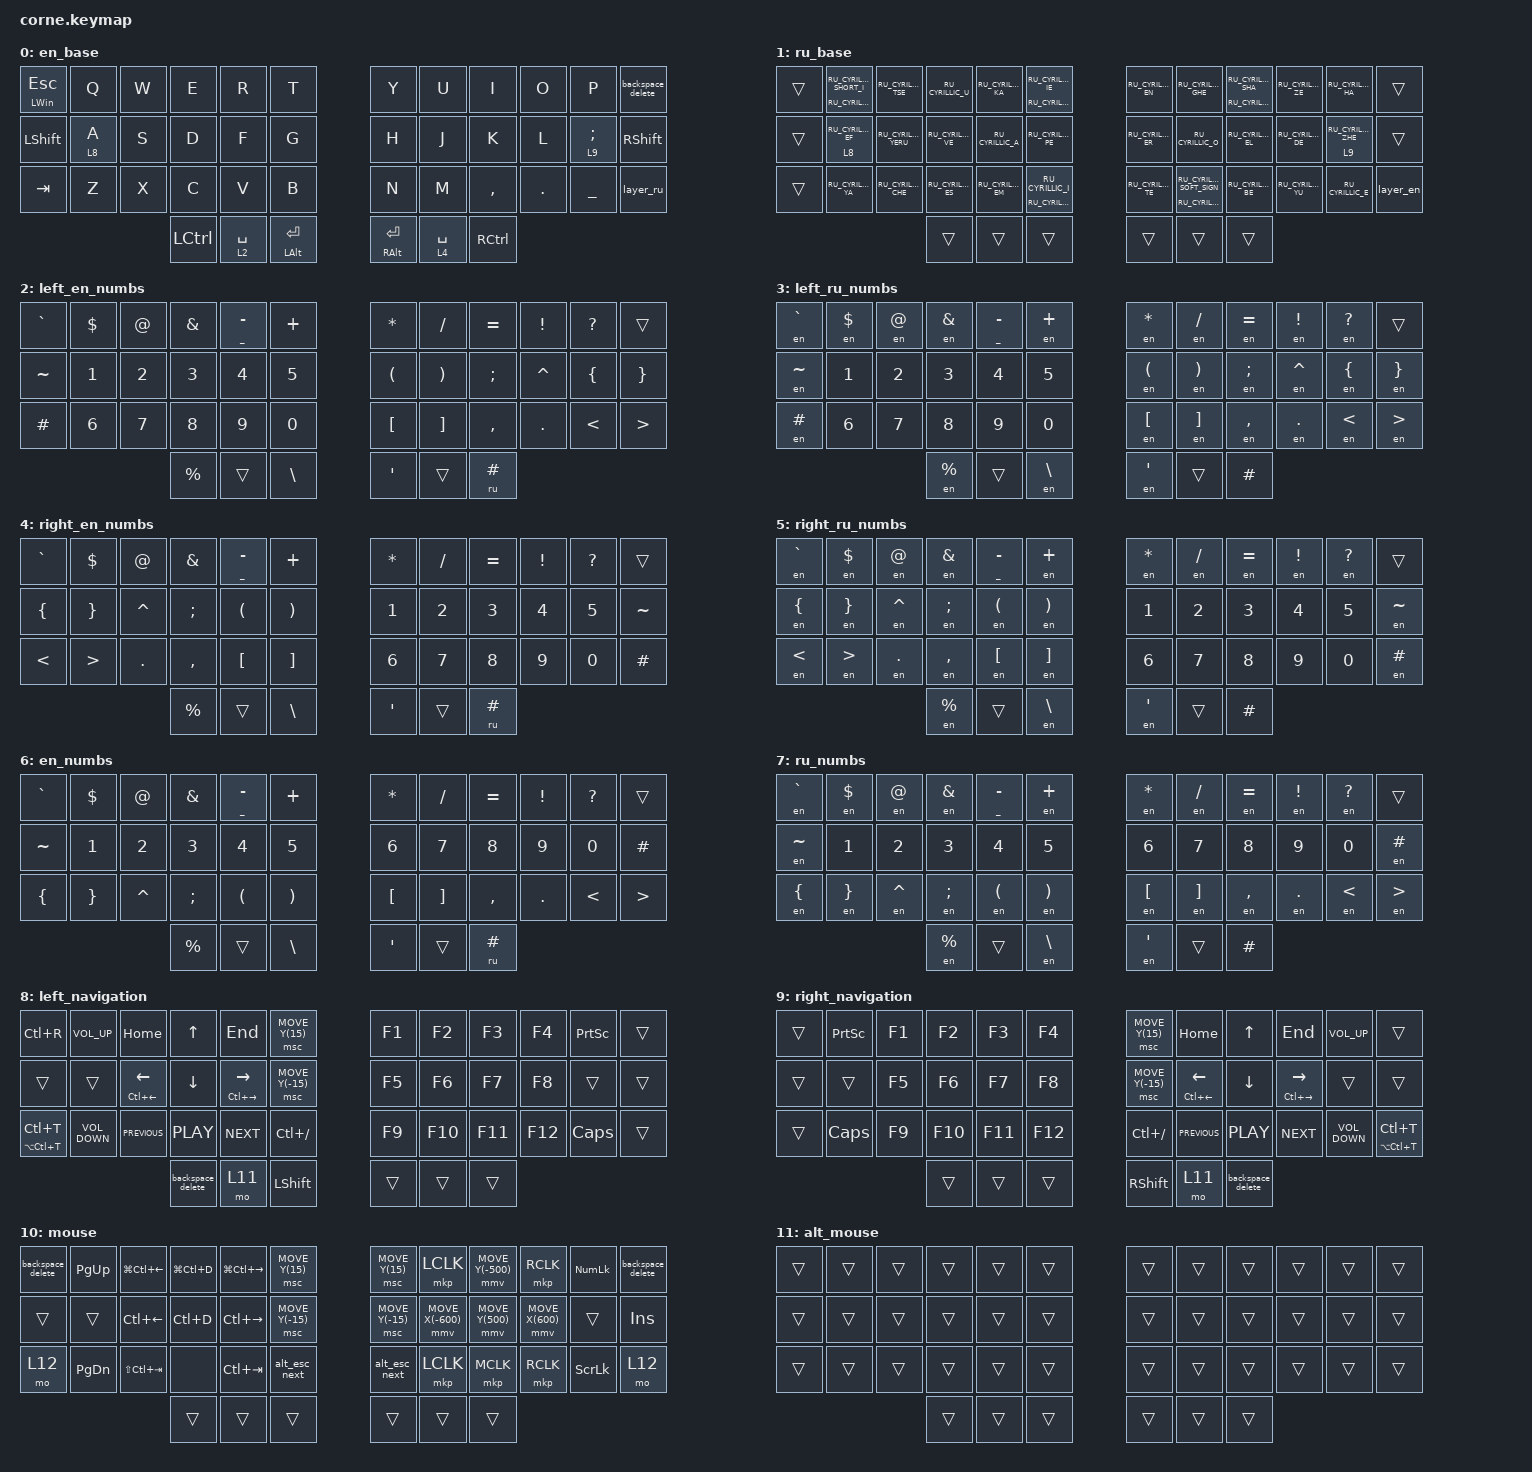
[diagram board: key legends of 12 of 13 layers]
/*
 * Copyright (c) 2020 The ZMK Contributors
 *
 * SPDX-License-Identifier: MIT
 */

#define ZMK_POINTING_DEFAULT_MOVE_VAL 1500  // default: 600
#define ZMK_POINTING_DEFAULT_SCRL_VAL 20    // default: 10

#include "keys_ru.h"
#include <behaviors.dtsi>
#include <dt-bindings/zmk/bt.h>
#include <dt-bindings/zmk/keys.h>
#include <dt-bindings/zmk/outputs.h>
#include <dt-bindings/zmk/pointing.h>

/ {
    combos { compatible = "zmk,combos"; };

    behaviors {
        hml: hml {
            compatible = "zmk,behavior-hold-tap";
            label = "HML";
            bindings = <&kp>, <&kp>;

            #binding-cells = <2>;
            tapping-term-ms = <220>;
            quick-tap-ms = <175>;
            flavor = "balanced";
            require-prior-idle-ms = <100>;
            hold-trigger-key-positions = <39 40 41 30 18 6 7 9 10 11 18 19 20 21 22 23 30 31 32 33 34 35 40 41 8 36 37 38>;
            hold-trigger-on-release;
        };

        hmr: hmr {
            compatible = "zmk,behavior-hold-tap";
            label = "HMR";
            bindings = <&kp>, <&kp>;

            #binding-cells = <2>;
            tapping-term-ms = <220>;
            quick-tap-ms = <175>;
            require-prior-idle-ms = <100>;
            flavor = "balanced";
            hold-trigger-key-positions = <0 1 2 3 4 5 12 13 14 15 16 17 24 25 26 27 28 29 36 37 38 39 40 41>;
            hold-trigger-on-release;
        };

        tkl: tkl {
            compatible = "zmk,behavior-hold-tap";
            label = "TKL";
            bindings = <&mo>, <&kp>;

            #binding-cells = <2>;
            tapping-term-ms = <220>;
            quick-tap-ms = <175>;
            flavor = "balanced";
            require-prior-idle-ms = <100>;
            hold-trigger-key-positions = <39 40 41 30 18 6 7 9 10 11 18 19 20 21 22 23 30 31 32 33 34 35 40 41 8 38 37 36>;
            hold-trigger-on-release;
        };

        tkr: tkr {
            compatible = "zmk,behavior-hold-tap";
            label = "TKR";
            bindings = <&mo>, <&kp>;

            #binding-cells = <2>;
            tapping-term-ms = <220>;
            quick-tap-ms = <175>;
            require-prior-idle-ms = <100>;
            flavor = "balanced";
            hold-trigger-key-positions = <0 1 2 3 4 5 12 13 14 15 16 17 24 25 26 27 28 29 36 37 38 39 40 41>;
            hold-trigger-on-release;
        };

        on: on {
            compatible = "zmk,behavior-toggle-layer";
            #binding-cells = <1>;
            toggle-mode = "on";
        };

        off: off {
            compatible = "zmk,behavior-toggle-layer";
            #binding-cells = <1>;
            toggle-mode = "off";
        };

        backspace_delete: backspace_delete {
            compatible = "zmk,behavior-mod-morph";
            label = "BACKSPACE_DELETE";
            bindings = <&hml LC(BACKSPACE) BACKSPACE>, <&hml LC(DELETE) DELETE>;

            #binding-cells = <0>;
            mods = <(MOD_LSFT|MOD_RSFT|MOD_LALT|MOD_RALT)>;
        };
    };

    macros {
        layer_en: layer_en {
            compatible = "zmk,behavior-macro";
            #binding-cells = <0>;
            bindings = <&off 1>, <&macro_tap>, <&kp LA(LS(NUMBER_0))>;

            label = "LAYER_EN";
        };

        layer_ru: layer_ru {
            compatible = "zmk,behavior-macro";
            #binding-cells = <0>;
            bindings = <&on 1>, <&macro_tap>, <&kp LA(LS(NUMBER_1))>;

            label = "LAYER_RU";
        };

        en: en {
            compatible = "zmk,behavior-macro-one-param";
            #binding-cells = <1>;
            bindings =
                <&macro_tap>,
                <&kp LA(LS(NUMBER_0))>,
                <&macro_press>,
                <&macro_param_1to1 &kp MACRO_PLACEHOLDER>,
                <&macro_pause_for_release>,
                <&macro_release>,
                <&macro_param_1to1 &kp MACRO_PLACEHOLDER>,
                <&macro_tap_time 30>,
                <&macro_tap>,
                <&kp LA(LS(NUMBER_1))>;

            label = "EN";
        };

        ru: ru {
            compatible = "zmk,behavior-macro-one-param";
            #binding-cells = <1>;
            bindings =
                <&macro_tap>,
                <&kp LA(LS(NUMBER_1))>,
                <&macro_press>,
                <&macro_param_1to1 &kp MACRO_PLACEHOLDER>,
                <&macro_pause_for_release>,
                <&macro_release>,
                <&macro_param_1to1 &kp MACRO_PLACEHOLDER>,
                <&macro_tap_time 30>,
                <&macro_tap>,
                <&kp LA(LS(NUMBER_0))>;

            label = "RU";
        };

        alt_esc_next: alt_tab_next {
            compatible = "zmk,behavior-macro";
            #binding-cells = <0>;
            bindings = <&macro_tap>, <&sk LEFT_ALT>, <&macro_tap>, <&kp ESC>;

            label = "ALT_TAB_NEXT";
        };
    };

    keymap {
        compatible = "zmk,keymap";

        en_base {
            // -----------------------------------------------------------------------------------------
            // |  TAB |  Q  |  W  |  E  |  R  |  T  |   |  Y  |  U   |  I  |  O  |  P  | BKSP |
            // | CTRL |  A  |  S  |  D  |  F  |  G  |   |  H  |  J   |  K  |  L  |  ;  |  '   |
            // | SHFT |  Z  |  X  |  C  |  V  |  B  |   |  N  |  M   |  ,  |  .  |  /  | ESC  |
            //                    | GUI | LWR | SPC |   | ENT | RSE  | ALT |

            bindings = <
&hml LEFT_WIN ESC  &kp Q     &kp W  &kp E      &kp R         &kp T                  &kp Y                 &kp U         &kp I      &kp O       &kp P             &backspace_delete
&kp LEFT_SHIFT     &tkl 8 A  &kp S  &kp D      &kp F         &kp G                  &kp H                 &kp J         &kp K      &kp L       &tkr 9 SEMICOLON  &kp RSHFT
&kp TAB            &kp Z     &kp X  &kp C      &kp V         &kp B                  &kp N                 &kp M         &kp COMMA  &kp PERIOD  &kp UNDERSCORE    &layer_ru
                                    &kp LCTRL  &tkl 2 SPACE  &hml LEFT_ALT ENTER    &hml RIGHT_ALT ENTER  &tkr 4 SPACE  &kp RCTRL
            >;
        };

        ru_base {
            bindings = <
&trans  &hml RU_CYRILLIC_I RU_CYRILLIC_SHORT_I  &kp RU_CYRILLIC_TSE   &kp RU_CYRILLIC_U   &kp RU_CYRILLIC_KA  &hml RU_CYRILLIC_IO RU_CYRILLIC_IE        &kp RU_CYRILLIC_EN  &kp RU_CYRILLIC_GHE                               &hml RU_CYRILLIC_SHCHA RU_CYRILLIC_SHA  &kp RU_CYRILLIC_ZE  &kp RU_CYRILLIC_HA      &trans
&trans  &tkl 8 RU_CYRILLIC_EF                   &kp RU_CYRILLIC_YERU  &kp RU_CYRILLIC_VE  &kp RU_CYRILLIC_A   &kp RU_CYRILLIC_PE                        &kp RU_CYRILLIC_ER  &kp RU_CYRILLIC_O                                 &kp RU_CYRILLIC_EL                      &kp RU_CYRILLIC_DE  &tkr 9 RU_CYRILLIC_ZHE  &trans
&trans  &kp RU_CYRILLIC_YA                      &kp RU_CYRILLIC_CHE   &kp RU_CYRILLIC_ES  &kp RU_CYRILLIC_EM  &hml RU_CYRILLIC_SHORT_I RU_CYRILLIC_I    &kp RU_CYRILLIC_TE  &hml RU_CYRILLIC_HARD_SIGN RU_CYRILLIC_SOFT_SIGN  &kp RU_CYRILLIC_BE                      &kp RU_CYRILLIC_YU  &kp RU_CYRILLIC_E       &layer_en
                                                                      &trans              &trans              &trans                                    &trans              &trans                                            &trans
            >;
        };

        left_en_numbs {
            bindings = <
&kp GRAVE  &kp DOLLAR    &kp AT_SIGN   &kp AMPERSAND  &hml UNDERSCORE MINUS  &kp PLUS         &kp ASTERISK          &kp SLASH              &kp EQUAL      &kp EXCLAMATION  &kp QUESTION    &trans
&kp TILDE  &kp N1        &kp NUMBER_2  &kp NUMBER_3   &kp NUMBER_4           &kp NUMBER_5     &kp LEFT_PARENTHESIS  &kp RIGHT_PARENTHESIS  &kp SEMICOLON  &kp CARET        &kp LEFT_BRACE  &kp RIGHT_BRACE
&kp HASH   &kp NUMBER_6  &kp NUMBER_7  &kp NUMBER_8   &kp NUMBER_9           &kp NUMBER_0     &kp LEFT_BRACKET      &kp RIGHT_BRACKET      &kp COMMA      &kp DOT          &kp LESS_THAN   &kp GREATER_THAN
                                       &kp PERCENT    &trans                 &kp BACKSLASH    &kp SINGLE_QUOTE      &trans                 &ru HASH
            >;
        };

        left_ru_numbs {
            bindings = <
&en GRAVE  &en DOLLAR    &en AT_SIGN   &en AMPERSAND  &hml UNDERSCORE MINUS  &en PLUS         &en ASTERISK          &en SLASH              &en EQUAL      &en EXCLAMATION  &en QUESTION    &trans
&en TILDE  &kp N1        &kp NUMBER_2  &kp NUMBER_3   &kp NUMBER_4           &kp NUMBER_5     &en LEFT_PARENTHESIS  &en RIGHT_PARENTHESIS  &en SEMICOLON  &en CARET        &en LEFT_BRACE  &en RIGHT_BRACE
&en HASH   &kp NUMBER_6  &kp NUMBER_7  &kp NUMBER_8   &kp NUMBER_9           &kp NUMBER_0     &en LEFT_BRACKET      &en RIGHT_BRACKET      &en COMMA      &en DOT          &en LESS_THAN   &en GREATER_THAN
                                       &en PERCENT    &trans                 &en BACKSLASH    &en SINGLE_QUOTE      &trans                 &kp HASH
            >;
        };

        right_en_numbs {
            bindings = <
&kp GRAVE       &kp DOLLAR        &kp AT_SIGN  &kp AMPERSAND  &hml UNDERSCORE MINUS  &kp PLUS                 &kp ASTERISK      &kp SLASH     &kp EQUAL     &kp EXCLAMATION  &kp QUESTION  &trans
&kp LEFT_BRACE  &kp RIGHT_BRACE   &kp CARET    &kp SEMICOLON  &kp LEFT_PARENTHESIS   &kp RIGHT_PARENTHESIS    &kp NUMBER_1      &kp NUMBER_2  &kp NUMBER_3  &kp NUMBER_4     &kp NUMBER_5  &kp TILDE
&kp LESS_THAN   &kp GREATER_THAN  &kp DOT      &kp COMMA      &kp LEFT_BRACKET       &kp RIGHT_BRACKET        &kp NUMBER_6      &kp NUMBER_7  &kp NUMBER_8  &kp NUMBER_9     &kp NUMBER_0  &kp HASH
                                               &kp PERCENT    &trans                 &kp BACKSLASH            &kp SINGLE_QUOTE  &trans        &ru HASH
            >;
        };

        right_ru_numbs {
            bindings = <
&en GRAVE       &en DOLLAR        &en AT_SIGN  &en AMPERSAND  &hml UNDERSCORE MINUS  &en PLUS                 &en ASTERISK      &en SLASH     &en EQUAL     &en EXCLAMATION  &en QUESTION  &trans
&en LEFT_BRACE  &en RIGHT_BRACE   &en CARET    &en SEMICOLON  &en LEFT_PARENTHESIS   &en RIGHT_PARENTHESIS    &kp NUMBER_1      &kp NUMBER_2  &kp NUMBER_3  &kp NUMBER_4     &kp NUMBER_5  &en TILDE
&en LESS_THAN   &en GREATER_THAN  &en DOT      &en COMMA      &en LEFT_BRACKET       &en RIGHT_BRACKET        &kp NUMBER_6      &kp NUMBER_7  &kp NUMBER_8  &kp NUMBER_9     &kp NUMBER_0  &en HASH
                                               &en PERCENT    &trans                 &en BACKSLASH            &en SINGLE_QUOTE  &trans        &kp HASH
            >;
        };

        en_numbs {
            bindings = <
&kp GRAVE       &kp DOLLAR       &kp AT_SIGN   &kp AMPERSAND  &hml UNDERSCORE MINUS  &kp PLUS                 &kp ASTERISK      &kp SLASH          &kp EQUAL     &kp EXCLAMATION  &kp QUESTION   &trans
&kp TILDE       &kp N1           &kp NUMBER_2  &kp NUMBER_3   &kp NUMBER_4           &kp NUMBER_5             &kp NUMBER_6      &kp NUMBER_7       &kp NUMBER_8  &kp NUMBER_9     &kp NUMBER_0   &kp HASH
&kp LEFT_BRACE  &kp RIGHT_BRACE  &kp CARET     &kp SEMICOLON  &kp LEFT_PARENTHESIS   &kp RIGHT_PARENTHESIS    &kp LEFT_BRACKET  &kp RIGHT_BRACKET  &kp COMMA     &kp DOT          &kp LESS_THAN  &kp GREATER_THAN
                                               &kp PERCENT    &trans                 &kp BACKSLASH            &kp SINGLE_QUOTE  &trans             &ru HASH
            >;
        };

        ru_numbs {
            bindings = <
&en GRAVE       &en DOLLAR       &en AT_SIGN   &en AMPERSAND  &hml UNDERSCORE MINUS  &en PLUS                 &en ASTERISK      &en SLASH          &en EQUAL     &en EXCLAMATION  &en QUESTION   &trans
&en TILDE       &kp N1           &kp NUMBER_2  &kp NUMBER_3   &kp NUMBER_4           &kp NUMBER_5             &kp NUMBER_6      &kp NUMBER_7       &kp NUMBER_8  &kp NUMBER_9     &kp NUMBER_0   &en HASH
&en LEFT_BRACE  &en RIGHT_BRACE  &en CARET     &en SEMICOLON  &en LEFT_PARENTHESIS   &en RIGHT_PARENTHESIS    &en LEFT_BRACKET  &en RIGHT_BRACKET  &en COMMA     &en DOT          &en LESS_THAN  &en GREATER_THAN
                                               &en PERCENT    &trans                 &en BACKSLASH            &en SINGLE_QUOTE  &trans             &kp HASH
            >;
        };

        left_navigation {
            bindings = <
&kp LC(R)             &kp C_VOLUME_UP    &kp HOME                        &kp UP_ARROW       &kp END                           &msc MOVE_Y(15)     &kp F1  &kp F2   &kp F3   &kp F4   &kp PRINTSCREEN  &trans
&trans                &trans             &hml LC(LEFT_ARROW) LEFT_ARROW  &kp DOWN_ARROW     &hml LC(RIGHT_ARROW) RIGHT_ARROW  &msc MOVE_Y(-15)    &kp F5  &kp F6   &kp F7   &kp F8   &trans           &trans
&hml LA(LC(T)) LC(T)  &kp C_VOLUME_DOWN  &kp C_PREVIOUS                  &kp C_PLAY         &kp C_NEXT                        &kp LC(SLASH)       &kp F9  &kp F10  &kp F11  &kp F12  &kp CAPSLOCK     &trans
                                                                         &backspace_delete  &mo 11                            &kp LEFT_SHIFT      &trans  &trans   &trans
            >;
        };

        right_navigation {
            bindings = <
&trans  &kp PRINTSCREEN  &kp F1  &kp F2   &kp F3   &kp F4     &msc MOVE_Y(15)   &kp HOME                        &kp UP_ARROW       &kp END                           &kp C_VOLUME_UP    &trans
&trans  &trans           &kp F5  &kp F6   &kp F7   &kp F8     &msc MOVE_Y(-15)  &hml LC(LEFT_ARROW) LEFT_ARROW  &kp DOWN_ARROW     &hml LC(RIGHT_ARROW) RIGHT_ARROW  &trans             &trans
&trans  &kp CAPSLOCK     &kp F9  &kp F10  &kp F11  &kp F12    &kp LC(SLASH)     &kp C_PREVIOUS                  &kp C_PLAY         &kp C_NEXT                        &kp C_VOLUME_DOWN  &hml LA(LC(T)) LC(T)
                                 &trans   &trans   &trans     &kp RIGHT_SHIFT   &mo 11                          &backspace_delete
            >;
        };

        mouse {
            bindings = <
&backspace_delete  &kp PAGE_UP    &kp LG(LC(LEFT_ARROW))  &kp LG(LC(D))  &kp LG(LC(RIGHT_ARROW))  &msc MOVE_Y(15)     &msc MOVE_Y(15)   &mkp LCLK          &mmv MOVE_Y(-500)  &mkp RCLK         &kp KP_NUMLOCK  &backspace_delete
&trans             &trans         &kp LC(LEFT_ARROW)      &kp LC(D)      &kp LC(RIGHT_ARROW)      &msc MOVE_Y(-15)    &msc MOVE_Y(-15)  &mmv MOVE_X(-600)  &mmv MOVE_Y(500)   &mmv MOVE_X(600)  &trans          &kp INSERT
&mo 12             &kp PAGE_DOWN  &kp LS(LC(TAB))         &none          &kp LC(TAB)              &alt_esc_next       &alt_esc_next     &mkp LCLK          &mkp MCLK          &mkp RCLK         &kp SCROLLLOCK  &mo 12
                                                          &trans         &trans                   &trans              &trans            &trans             &trans
            >;
        };

        alt_mouse {
            bindings = <
&trans  &trans  &trans  &trans  &trans  &trans    &trans  &trans  &trans  &trans  &trans  &trans
&trans  &trans  &trans  &trans  &trans  &trans    &trans  &trans  &trans  &trans  &trans  &trans
&trans  &trans  &trans  &trans  &trans  &trans    &trans  &trans  &trans  &trans  &trans  &trans
                        &trans  &trans  &trans    &trans  &trans  &trans
            >;
        };

        settings {
            bindings = <
&soft_off   &none  &none  &none         &none         &studio_unlock    &bt BT_CLR_ALL  &none  &bt BT_SEL 0  &bt BT_SEL 1  &none  &soft_off
&sys_reset  &none  &none  &none         &none         &none             &bt BT_CLR      &none  &bt BT_SEL 2  &bt BT_SEL 3  &none  &sys_reset
&none       &none  &none  &none         &none         &bootloader       &bootloader     &none  &bt BT_SEL 4  &none         &none  &none
                          &out OUT_USB  &out OUT_TOG  &out OUT_BLE      &bt BT_PRV      &none  &bt BT_NXT
            >;
        };
    };

    conditional_layers {
        compatible = "zmk,conditional-layers";

        on_mouse {
            if-layers = <8 9>;
            then-layer = <10>;
        };

        ru_numbs {
            if-layers = <1 6>;
            then-layer = <7>;
        };

        left_ru_numbs {
            if-layers = <1 2>;
            then-layer = <3>;
        };

        right_ru_numbs {
            if-layers = <1 4>;
            then-layer = <5>;
        };

        on_numbs {
            if-layers = <2 4>;
            then-layer = <6>;
        };

        on_mouse_alt {
            if-layers = <11>;
            then-layer = <10>;
        };
    };
};
